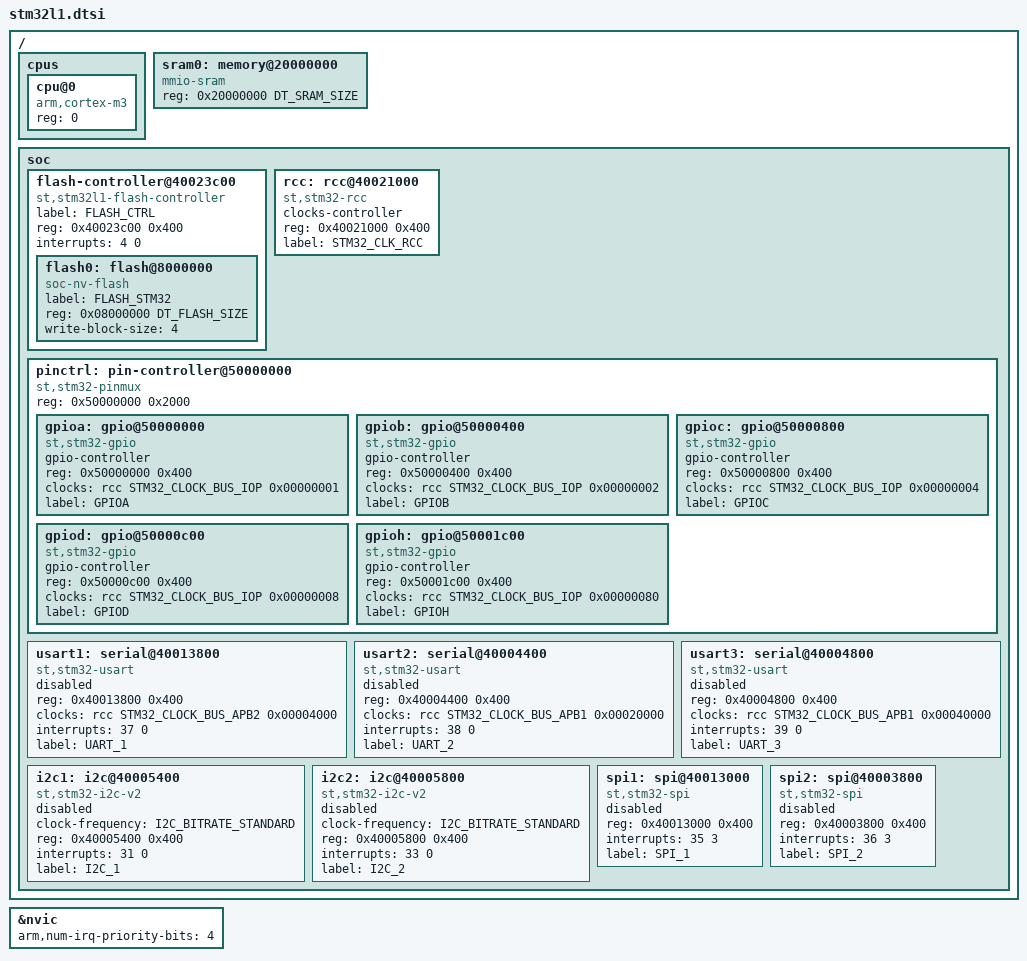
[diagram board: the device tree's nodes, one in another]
/*
 * Copyright (c) 2018 Endre Karlson <endre.karlson@gmail.com>
 *
 * SPDX-License-Identifier: Apache-2.0
 */

#include <st/stm32l1-pinctrl.dtsi>
#include <arm/armv7-m.dtsi>
#include <st/mem.h>
#include <dt-bindings/clock/stm32_clock.h>
#include <dt-bindings/i2c/i2c.h>
#include <dt-bindings/gpio/gpio.h>

/ {
	cpus {
		#address-cells = <1>;
		#size-cells = <0>;

		cpu@0 {
			device_type = "cpu";
			compatible = "arm,cortex-m3";
			reg = <0>;
		};
	};

	sram0: memory@20000000 {
		device_type = "memory";
		compatible = "mmio-sram";
		reg = <0x20000000 DT_SRAM_SIZE>;
	};

	soc {
		flash-controller@40023c00 {
			compatible = "st,stm32l1-flash-controller";
			label = "FLASH_CTRL";
			reg = <0x40023c00 0x400>;
			interrupts = <4 0>;

			#address-cells = <1>;
			#size-cells = <1>;

			flash0: flash@8000000 {
				compatible = "soc-nv-flash";
				label = "FLASH_STM32";
				reg = <0x08000000 DT_FLASH_SIZE>;

				write-block-size = <4>;
			};
		};

		rcc: rcc@40021000 {
			compatible = "st,stm32-rcc";
			clocks-controller;
			#clock-cells = <2>;
			reg = <0x40021000 0x400>;
			label = "STM32_CLK_RCC";
		};

		pinctrl: pin-controller@50000000 {
			compatible = "st,stm32-pinmux";
			#address-cells = <1>;
			#size-cells = <1>;
			reg = <0x50000000 0x2000>;

			gpioa: gpio@50000000 {
				compatible = "st,stm32-gpio";
				gpio-controller;
				#gpio-cells = <2>;
				reg = <0x50000000 0x400>;
				clocks = <&rcc STM32_CLOCK_BUS_IOP 0x00000001>;
				label = "GPIOA";
			};

			gpiob: gpio@50000400 {
				compatible = "st,stm32-gpio";
				gpio-controller;
				#gpio-cells = <2>;
				reg = <0x50000400 0x400>;
				clocks = <&rcc STM32_CLOCK_BUS_IOP 0x00000002>;
				label = "GPIOB";
			};

			gpioc: gpio@50000800 {
				compatible = "st,stm32-gpio";
				gpio-controller;
				#gpio-cells = <2>;
				reg = <0x50000800 0x400>;
				clocks = <&rcc STM32_CLOCK_BUS_IOP 0x00000004>;
				label = "GPIOC";
			};

			gpiod: gpio@50000c00 {
				compatible = "st,stm32-gpio";
				gpio-controller;
				#gpio-cells = <2>;
				reg = <0x50000c00 0x400>;
				clocks = <&rcc STM32_CLOCK_BUS_IOP 0x00000008>;
				label = "GPIOD";
			};

			gpioh: gpio@50001c00 {
				compatible = "st,stm32-gpio";
				gpio-controller;
				#gpio-cells = <2>;
				reg = <0x50001c00 0x400>;
				clocks = <&rcc STM32_CLOCK_BUS_IOP 0x00000080>;
				label = "GPIOH";
			};
		};

		usart1: serial@40013800 {
			compatible = "st,stm32-usart", "st,stm32-uart";
			reg = <0x40013800 0x400>;
			clocks = <&rcc STM32_CLOCK_BUS_APB2 0x00004000>;
			interrupts = <37 0>;
			status = "disabled";
			label = "UART_1";
		};

		usart2: serial@40004400 {
			compatible = "st,stm32-usart", "st,stm32-uart";
			reg = <0x40004400 0x400>;
			clocks = <&rcc STM32_CLOCK_BUS_APB1 0x00020000>;
			interrupts = <38 0>;
			status = "disabled";
			label = "UART_2";
		};

		usart3: serial@40004800 {
			compatible = "st,stm32-usart", "st,stm32-uart";
			reg = <0x40004800 0x400>;
			clocks = <&rcc STM32_CLOCK_BUS_APB1 0x00040000>;
			interrupts = <39 0>;
			status = "disabled";
			label = "UART_3";
		};

		i2c1: i2c@40005400 {
			compatible = "st,stm32-i2c-v2";
			clock-frequency = <I2C_BITRATE_STANDARD>;
			#address-cells = <1>;
			#size-cells = <0>;
			reg = <0x40005400 0x400>;
			interrupts = <31 0>;
			interrupt-names = "combined";
			status = "disabled";
			label= "I2C_1";
		};

		i2c2: i2c@40005800 {
			compatible = "st,stm32-i2c-v2";
			clock-frequency = <I2C_BITRATE_STANDARD>;
			#address-cells = <1>;
			#size-cells = <0>;
			reg = <0x40005800 0x400>;
			interrupts = <33 0>;
			interrupt-names = "combined";
			status = "disabled";
			label= "I2C_2";
		};

		spi1: spi@40013000 {
			compatible = "st,stm32-spi";
			#address-cells = <1>;
			#size-cells = <0>;
			reg = <0x40013000 0x400>;
			interrupts = <35 3>;
			status = "disabled";
			label = "SPI_1";
		};

		spi2: spi@40003800 {
			compatible = "st,stm32-spi";
			#address-cells = <1>;
			#size-cells = <0>;
			reg = <0x40003800 0x400>;
			interrupts = <36 3>;
			status = "disabled";
			label = "SPI_2";
		};
	};
};

&nvic {
	arm,num-irq-priority-bits = <4>;
};
